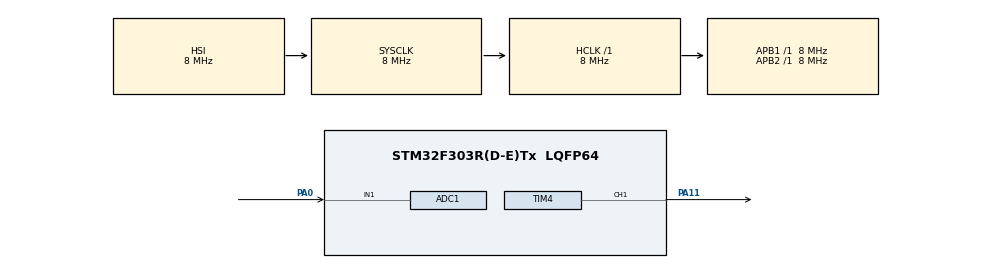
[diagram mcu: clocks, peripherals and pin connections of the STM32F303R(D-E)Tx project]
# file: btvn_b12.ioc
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ADC1.Channel-0\#ChannelRegularConversion=ADC_CHANNEL_1
ADC1.ContinuousConvMode=ENABLE
ADC1.EOCSelection=ADC_EOC_SEQ_CONV
ADC1.NbrOfConversionFlag=1
ADC1.Offset-0\#ChannelRegularConversion=0
ADC1.OffsetNumber-0\#ChannelRegularConversion=ADC_OFFSET_NONE
ADC1.Rank-0\#ChannelRegularConversion=1
ADC1.Resolution=ADC_RESOLUTION_6B
ADC1.SamplingTime-0\#ChannelRegularConversion=ADC_SAMPLETIME_601CYCLES_5
ADC1.master=1
Mcu.Family=STM32F3
Mcu.Name=STM32F303R(D-E)Tx
Mcu.Package=LQFP64
NVIC.ADC1_2_IRQn=true\:0\:0\:false\:false\:true\:true\:true
NVIC.PriorityGroup=NVIC_PRIORITYGROUP_4
PA0.Mode=IN1-Single-Ended
PA0.Signal=ADC1_IN1
PA11.Signal=S_TIM4_CH1
PA13.Mode=Serial_Wire
PA13.Signal=SYS_JTMS-SWDIO
PA14.Mode=Serial_Wire
PA14.Signal=SYS_JTCK-SWCLK
ProjectManager.HeapSize=0x200
ProjectManager.StackSize=0x400
ProjectManager.TargetToolchain=STM32CubeIDE
RCC.AHBFreq_Value=8000000
RCC.APB1Freq_Value=8000000
RCC.APB2Freq_Value=8000000
RCC.CortexFreq_Value=8000000
RCC.HSE_VALUE=8000000
RCC.HSI_VALUE=8000000
RCC.LSE_VALUE=32768
RCC.SYSCLKFreq_VALUE=8000000
RCC.USBFreq_Value=16000000
SH.S_TIM4_CH1.0=TIM4_CH1,PWM Generation1 CH1
TIM4.Channel-PWM\ Generation1\ CH1=TIM_CHANNEL_1
TIM4.Period=99
TIM4.Prescaler=79
TIM4.Pulse-PWM\ Generation1\ CH1=0
VP_TIM4_VS_ClockSourceINT.Mode=Internal
board=custom

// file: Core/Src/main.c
/* USER CODE BEGIN Header */
/**
  ******************************************************************************
  * @file           : main.c
  * @brief          : Main program body
  ******************************************************************************
  * @attention
  *
  * <h2><center>&copy; Copyright (c) 2021 STMicroelectronics.
  * All rights reserved.</center></h2>
  *
  * This software component is licensed by ST under BSD 3-Clause license,
  * the "License"; You may not use this file except in compliance with the
  * License. You may obtain a copy of the License at:
  *                        opensource.org/licenses/BSD-3-Clause
  *
  ******************************************************************************
  */
/* USER CODE END Header */
#include "main.h"

ADC_HandleTypeDef hadc1;

TIM_HandleTypeDef htim4;

/* USER CODE BEGIN PV */
uint8_t value_adc = 0;
/* USER CODE END PV */

void SystemClock_Config(void);
static void MX_GPIO_Init(void);
static void MX_ADC1_Init(void);
static void MX_TIM4_Init(void);

/* USER CODE BEGIN 0 */
void HAL_ADC_ConvCpltCallback(ADC_HandleTypeDef* hadc){
	value_adc = HAL_ADC_GetValue(&hadc1);
}
/* USER CODE END 0 */

int main(void)
{

  /* MCU Configuration--------------------------------------------------------*/

  /* Reset of all peripherals, Initializes the Flash interface and the Systick. */
  HAL_Init();

  /* Configure the system clock */
  SystemClock_Config();

  /* Initialize all configured peripherals */
  MX_GPIO_Init();
  MX_ADC1_Init();
  MX_TIM4_Init();
  /* USER CODE BEGIN 2 */
  HAL_ADCEx_Calibration_Start(&hadc1,ADC_SINGLE_ENDED);
  HAL_Delay(50);
  HAL_ADC_Start_IT(&hadc1);
  uint8_t duty = 0;
  HAL_TIM_PWM_Start(&htim4,TIM_CHANNEL_1);
  /* USER CODE END 2 */

  /* Infinite loop */
  /* USER CODE BEGIN WHILE */
  while (1)
  {
	  duty = (value_adc * 99)/63;
	  TIM4 ->CCR1 = duty;
	  HAL_Delay(20);
    /* USER CODE END WHILE */

  }
}

void SystemClock_Config(void)
{
  RCC_OscInitTypeDef RCC_OscInitStruct = {0};
  RCC_ClkInitTypeDef RCC_ClkInitStruct = {0};
  RCC_PeriphCLKInitTypeDef PeriphClkInit = {0};

  /** Initializes the RCC Oscillators according to the specified parameters
  * in the RCC_OscInitTypeDef structure.
  */
  RCC_OscInitStruct.OscillatorType = RCC_OSCILLATORTYPE_HSI;
  RCC_OscInitStruct.HSIState = RCC_HSI_ON;
  RCC_OscInitStruct.HSICalibrationValue = RCC_HSICALIBRATION_DEFAULT;
  RCC_OscInitStruct.PLL.PLLState = RCC_PLL_ON;
  RCC_OscInitStruct.PLL.PLLSource = RCC_PLLSOURCE_HSI;
  RCC_OscInitStruct.PLL.PLLMUL = RCC_PLL_MUL2;
  RCC_OscInitStruct.PLL.PREDIV = RCC_PREDIV_DIV1;
  if (HAL_RCC_OscConfig(&RCC_OscInitStruct) != HAL_OK)
  {
    Error_Handler();
  }
  /** Initializes the CPU, AHB and APB buses clocks
  */
  RCC_ClkInitStruct.ClockType = RCC_CLOCKTYPE_HCLK|RCC_CLOCKTYPE_SYSCLK
                              |RCC_CLOCKTYPE_PCLK1|RCC_CLOCKTYPE_PCLK2;
  RCC_ClkInitStruct.SYSCLKSource = RCC_SYSCLKSOURCE_HSI;
  RCC_ClkInitStruct.AHBCLKDivider = RCC_SYSCLK_DIV1;
  RCC_ClkInitStruct.APB1CLKDivider = RCC_HCLK_DIV1;
  RCC_ClkInitStruct.APB2CLKDivider = RCC_HCLK_DIV1;

  if (HAL_RCC_ClockConfig(&RCC_ClkInitStruct, FLASH_LATENCY_0) != HAL_OK)
  {
    Error_Handler();
  }
  PeriphClkInit.PeriphClockSelection = RCC_PERIPHCLK_ADC12|RCC_PERIPHCLK_TIM34;
  PeriphClkInit.Adc12ClockSelection = RCC_ADC12PLLCLK_DIV1;
  PeriphClkInit.Tim34ClockSelection = RCC_TIM34CLK_HCLK;
  if (HAL_RCCEx_PeriphCLKConfig(&PeriphClkInit) != HAL_OK)
  {
    Error_Handler();
  }
}

static void MX_ADC1_Init(void)
{

  ADC_MultiModeTypeDef multimode = {0};
  ADC_ChannelConfTypeDef sConfig = {0};

  /** Common config
  */
  hadc1.Instance = ADC1;
  hadc1.Init.ClockPrescaler = ADC_CLOCK_ASYNC_DIV1;
  hadc1.Init.Resolution = ADC_RESOLUTION_6B;
  hadc1.Init.ScanConvMode = ADC_SCAN_DISABLE;
  hadc1.Init.ContinuousConvMode = ENABLE;
  hadc1.Init.DiscontinuousConvMode = DISABLE;
  hadc1.Init.ExternalTrigConvEdge = ADC_EXTERNALTRIGCONVEDGE_NONE;
  hadc1.Init.ExternalTrigConv = ADC_SOFTWARE_START;
  hadc1.Init.DataAlign = ADC_DATAALIGN_RIGHT;
  hadc1.Init.NbrOfConversion = 1;
  hadc1.Init.DMAContinuousRequests = DISABLE;
  hadc1.Init.EOCSelection = ADC_EOC_SEQ_CONV;
  hadc1.Init.LowPowerAutoWait = DISABLE;
  hadc1.Init.Overrun = ADC_OVR_DATA_OVERWRITTEN;
  if (HAL_ADC_Init(&hadc1) != HAL_OK)
  {
    Error_Handler();
  }
  /** Configure the ADC multi-mode
  */
  multimode.Mode = ADC_MODE_INDEPENDENT;
  if (HAL_ADCEx_MultiModeConfigChannel(&hadc1, &multimode) != HAL_OK)
  {
    Error_Handler();
  }
  /** Configure Regular Channel
  */
  sConfig.Channel = ADC_CHANNEL_1;
  sConfig.Rank = ADC_REGULAR_RANK_1;
  sConfig.SingleDiff = ADC_SINGLE_ENDED;
  sConfig.SamplingTime = ADC_SAMPLETIME_601CYCLES_5;
  sConfig.OffsetNumber = ADC_OFFSET_NONE;
  sConfig.Offset = 0;
  if (HAL_ADC_ConfigChannel(&hadc1, &sConfig) != HAL_OK)
  {
    Error_Handler();
  }

}

static void MX_TIM4_Init(void)
{

  TIM_ClockConfigTypeDef sClockSourceConfig = {0};
  TIM_MasterConfigTypeDef sMasterConfig = {0};
  TIM_OC_InitTypeDef sConfigOC = {0};

  htim4.Instance = TIM4;
  htim4.Init.Prescaler = 79;
  htim4.Init.CounterMode = TIM_COUNTERMODE_UP;
  htim4.Init.Period = 99;
  htim4.Init.ClockDivision = TIM_CLOCKDIVISION_DIV1;
  htim4.Init.AutoReloadPreload = TIM_AUTORELOAD_PRELOAD_DISABLE;
  if (HAL_TIM_Base_Init(&htim4) != HAL_OK)
  {
    Error_Handler();
  }
  sClockSourceConfig.ClockSource = TIM_CLOCKSOURCE_INTERNAL;
  if (HAL_TIM_ConfigClockSource(&htim4, &sClockSourceConfig) != HAL_OK)
  {
    Error_Handler();
  }
  if (HAL_TIM_PWM_Init(&htim4) != HAL_OK)
  {
    Error_Handler();
  }
  sMasterConfig.MasterOutputTrigger = TIM_TRGO_RESET;
  sMasterConfig.MasterSlaveMode = TIM_MASTERSLAVEMODE_DISABLE;
  if (HAL_TIMEx_MasterConfigSynchronization(&htim4, &sMasterConfig) != HAL_OK)
  {
    Error_Handler();
  }
  sConfigOC.OCMode = TIM_OCMODE_PWM1;
  sConfigOC.Pulse = 0;
  sConfigOC.OCPolarity = TIM_OCPOLARITY_HIGH;
  sConfigOC.OCFastMode = TIM_OCFAST_DISABLE;
  if (HAL_TIM_PWM_ConfigChannel(&htim4, &sConfigOC, TIM_CHANNEL_1) != HAL_OK)
  {
    Error_Handler();
  }
  HAL_TIM_MspPostInit(&htim4);

}

static void MX_GPIO_Init(void)
{

  /* GPIO Ports Clock Enable */
  __HAL_RCC_GPIOA_CLK_ENABLE();

}

void Error_Handler(void)
{
  __disable_irq();
  while (1)
  {
  }
}

/************************ (C) COPYRIGHT STMicroelectronics *****END OF FILE****/
